# ESP32-H21 register map
Vendor: ESPRESSIF SYSTEMS (SHANGHAI) CO., LTD.; Series: ESP32 H-Series; File version: 1
CPU: RV32IMAC r0p0, little endian, no MPU, no FPU, 0 interrupt priority bits
Address unit: 32 bits
Registers are 32-bit, read-write, reset 0x0 unless marked. A register's access mark holds for its fields unless they carry their own. Offsets are from the block's base; [hi:lo] are bit positions; {n}, {i} and the like mark numbered series.

## SHA — SHA (Secure Hash Algorithm) Accelerator
Base 0x60089000
0x00 MODE — Initial configuration register.
  [2:0] MODE — Sha mode.
0x04 T_STRING — SHA 512/t configuration register 0.
  [31:0] T_STRING — Sha t_string (used if and only if mode == SHA_512/t).
0x08 T_LENGTH — SHA 512/t configuration register 1.
  [5:0] T_LENGTH — Sha t_length (used if and only if mode == SHA_512/t).
0x0C DMA_BLOCK_NUM — DMA configuration register 0.
  [5:0] DMA_BLOCK_NUM — Dma-sha block number.
0x10 START ro — Typical SHA configuration register 0.
  [31:1] START — Reserved.
0x14 CONTINUE ro — Typical SHA configuration register 1.
  [31:1] CONTINUE — Reserved.
0x18 BUSY ro
  [0] STATE — Sha busy state. 1'b0: idle. 1'b1: busy.
0x1C DMA_START wo — DMA configuration register 1.
  [0] DMA_START — Start dma-sha.
0x20 DMA_CONTINUE wo — DMA configuration register 2.
  [0] DMA_CONTINUE — Continue dma-sha.
0x24 CLEAR_IRQ wo — Interrupt clear register.
  [0] CLEAR_INTERRUPT — Clear sha interrupt.
0x28 IRQ_ENA — Interrupt enable register.
  [0] INTERRUPT_ENA — Sha interrupt enable register. 1'b0: disable(default). 1'b1: enable.
0x2C DATE reset 0x20201229
  [29:0] DATE — Sha date information/ sha version information.
{0x40+i} H_MEM[{i}] (i=0..63) 8-bit access not given — Sha H memory which contains intermediate hash or finial hash.
{0x80+i} M_MEM[{i}] (i=0..63) 8-bit access not given — Sha M memory which contains message.

## SOC_ETM — Event Task Matrix
Base 0x60013000
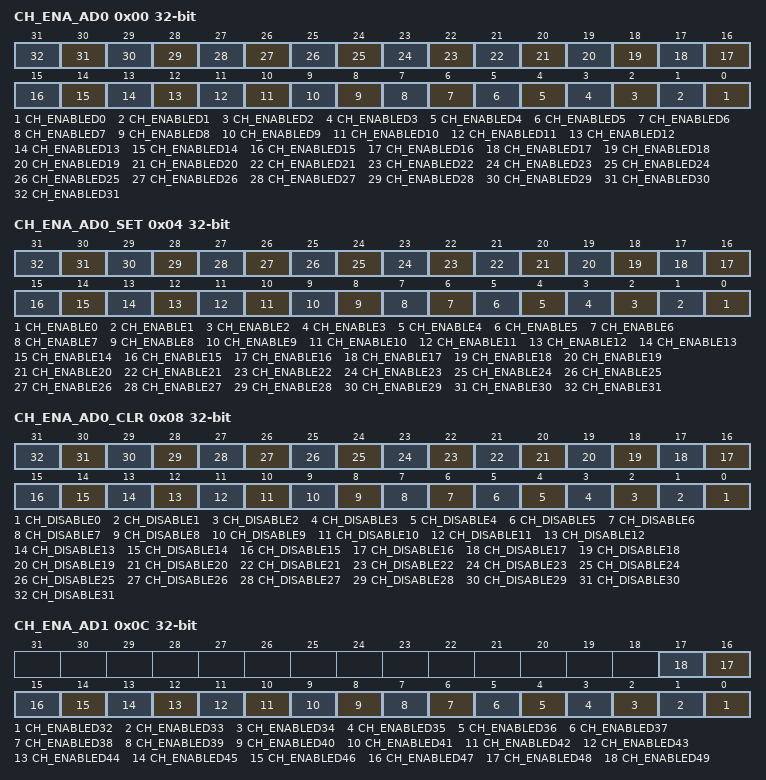
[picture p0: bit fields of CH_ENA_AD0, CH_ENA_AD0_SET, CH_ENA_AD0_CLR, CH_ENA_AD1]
0x00 CH_ENA_AD0 — Channel enable status register
  [n] CH_ENABLED{n} (n=0..31) — Represents channel{n} enable status.\\0: Disable\\1: Enable\\
0x04 CH_ENA_AD0_SET wo — Channel enable register
  [n] CH_ENABLE{n} (n=0..31) — Configures whether or not to enable channel{n}.\\0: Invalid. No effect\\1: Enable\\
0x08 CH_ENA_AD0_CLR wo — Channel disable register
  [n] CH_DISABLE{n} (n=0..31) — Configures whether or not to disable channel{n}.\\0: Invalid. No effect\\1: Clear\\
0x0C CH_ENA_AD1 — Channel enable status register
  [n-32] CH_ENABLED{n} (n=32..49) — Represents channel{n} enable status.\\0: Disable\\1: Enable\\
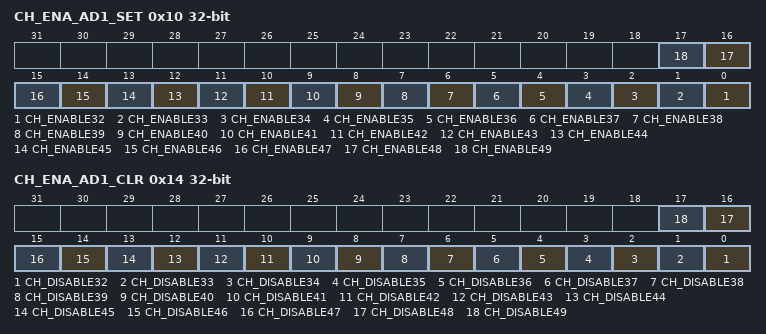
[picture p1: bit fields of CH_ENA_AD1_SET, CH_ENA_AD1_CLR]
0x10 CH_ENA_AD1_SET wo — Channel enable register
  [n-32] CH_ENABLE{n} (n=32..49) — Configures whether or not to enable channel{n}.\\0: Invalid. No effect\\1: Enable\\
0x14 CH_ENA_AD1_CLR wo — Channel disable register
  [n-32] CH_DISABLE{n} (n=32..49) — Configures whether or not to disable channel{n}.\\0: Invalid. No effect\\1: Clear\\
{0x18+8i} CH{i}_EVT_ID (i=0..49) — Channel{i} event ID register
  [7:0] CH_EVT_ID — Configures the event ID of channel%s.
{0x1C+8i} CH{i}_TASK_ID (i=0..49) — Channel{i} task ID register
  [7:0] CH_TASK_ID — Configures the task ID of channel%s.
0x1A8 CLK_EN — ETM clock enable register
  [0] CLK_EN — Configures resister clock gating.\\ 0: Support clock only when application writes registers\\ 1: Force on clock gating for registers\\
0x1AC DATE reset 0x2203092 — Version control register
  [27:0] DATE — Version control register.

## TEE — TEE Peripheral
Base 0x60098000
0x00 M0_MODE_CTRL — Tee mode control register
  [1:0] M0_MODE — M0 security level mode: 2'd3: ree_mode2. 2'd2: ree_mode1. 2'd1: ree_mode0. 2'd0: tee_mode
0x04 M1_MODE_CTRL reset 0x3 — Tee mode control register
  [1:0] M1_MODE — M1 security level mode: 2'd3: ree_mode2. 2'd2: ree_mode1. 2'd1: ree_mode0. 2'd0: tee_mode
0x08 M2_MODE_CTRL — Tee mode control register
  [1:0] M2_MODE — M2 security level mode: 2'd3: ree_mode2. 2'd2: ree_mode1. 2'd1: ree_mode0. 2'd0: tee_mode
{0x0+4i} M{i}_MODE_CTRL reset 0x3 (i=3..31) — Tee mode control register
  [1:0] M{i}_MODE — M{i} security level mode: 2'd3: ree_mode2. 2'd2: ree_mode1. 2'd1: ree_mode0. 2'd0: tee_mode
0x80 CLOCK_GATE reset 0x1 — Clock gating register
  [0] CLK_EN — reg_clk_en
0xFFC DATE reset 0x2205282 — Version register
  [27:0] DATE — reg_tee_date

## TRACE — RISC-V Trace Encoder
Base 0x600C0000
0x00 MEM_START_ADDR
  [31:0] MEM_STAET_ADDR — The start address of trace memory
0x04 MEM_END_ADDR reset 0xFFFFFFFF
  [31:0] MEM_END_ADDR — The end address of trace memory
0x08 MEM_CURRENT_ADDR ro
  [31:0] MEM_CURRENT_ADDR — current_mem_addr,indicate that next writing addr
0x0C MEM_ADDR_UPDATE wo
  [0] MEM_CURRENT_ADDR_UPDATE — when set this reg, the current_mem_addr will update to start_addr
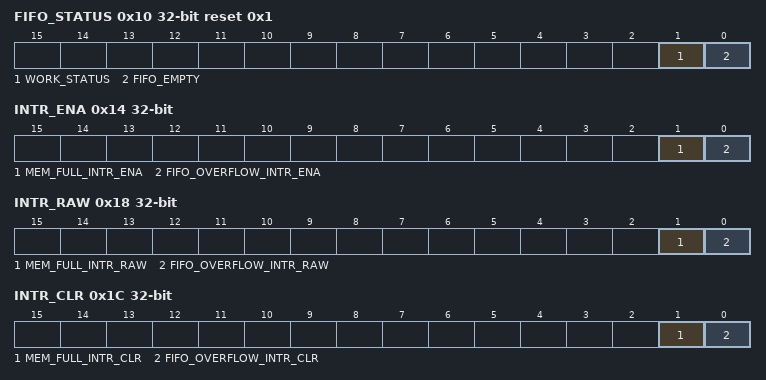
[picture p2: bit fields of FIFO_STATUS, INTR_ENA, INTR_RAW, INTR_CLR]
0x10 FIFO_STATUS ro reset 0x1
  [1] WORK_STATUS — mem_full interrupt status
  [0] FIFO_EMPTY — 1 indicate that fifo is empty
0x14 INTR_ENA — interrupt enable register
  [1] MEM_FULL_INTR_ENA — Set 1 enable mem_full interrupt
  [0] FIFO_OVERFLOW_INTR_ENA — Set 1 enable fifo_overflow interrupt
0x18 INTR_RAW ro — interrupt status register
  [1] MEM_FULL_INTR_RAW — mem_full interrupt status
  [0] FIFO_OVERFLOW_INTR_RAW — fifo_overflow interrupt status
0x1C INTR_CLR wo — interrupt clear register
  [1] MEM_FULL_INTR_CLR — Set 1 clr mem full interrupt
  [0] FIFO_OVERFLOW_INTR_CLR — Set 1 clr fifo overflow interrupt
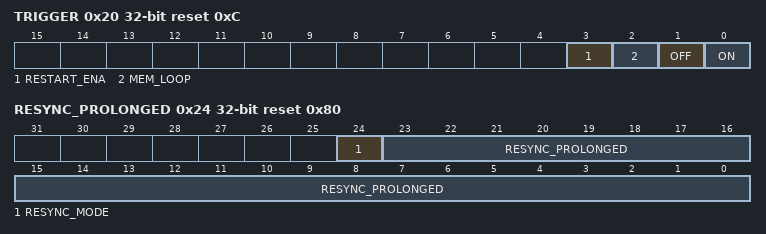
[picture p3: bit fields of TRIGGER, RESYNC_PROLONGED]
0x20 TRIGGER access per field reset 0xC
  [3] RESTART_ENA rw — enable encoder auto-restart, when lost package, the encoder will end, if enable auto-restart, when fifo empty, encoder will restart and send a sync package.
  [2] MEM_LOOP rw — if this reg is 1, trace will loop wrtie trace_mem. If is 0, when mem_current_addr at mem_end_addr, it will stop at the mem_end_addr
  [1] OFF wo — set 1 stop trace.
  [0] ON wo — [0] set 1 start trace.
0x24 RESYNC_PROLONGED reset 0x80 — resync configuration register
  [24] RESYNC_MODE — resyc mode sel: 0: default, cycle count 1: package num count
  [23:0] RESYNC_PROLONGED — count number, when count to this value, send a sync package
0x28 CLOCK_GATE reset 0x1 — Clock gate control register
  [0] CLK_EN — The bit is used to enable clock gate when access all registers in this module.
0x3FC DATE reset 0x2203030 — Version control register
  [27:0] DATE — version control register. Note that this default value stored is the latest date when the hardware logic was updated.
